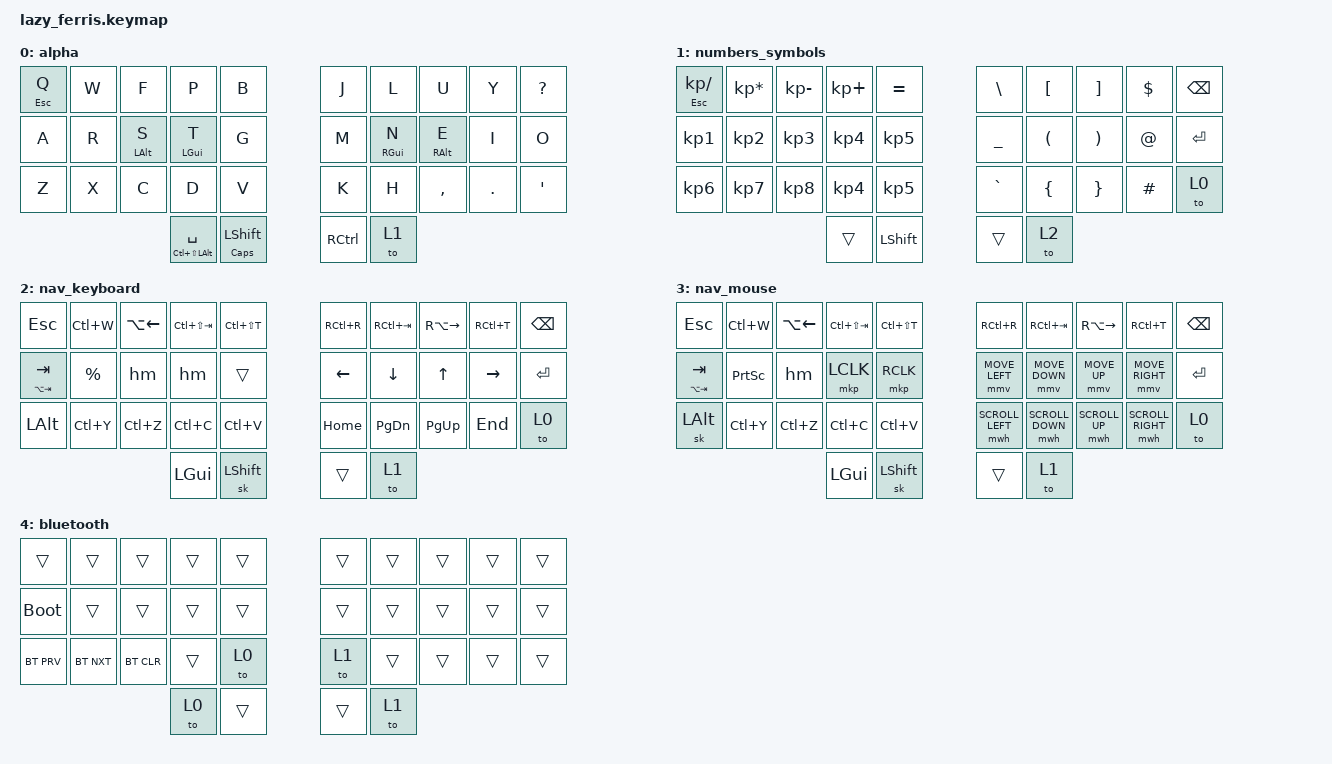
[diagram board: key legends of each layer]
/*
 * Copyright (c) 2020 The ZMK Contributors
 *
 * SPDX-License-Identifier: MIT
 */

#include <behaviors.dtsi>
#include <dt-bindings/zmk/keys.h>
#include <dt-bindings/zmk/bt.h>
#include <dt-bindings/zmk/mouse.h>

&mt {
    tapping_term_ms = <200>;
    flavor = "tap-preferred";
};

// Layers
#define ALPHA   0
#define SYMBOLS 1
#define KBNAV   2
#define MSNAV   3	
#define BLTH    4

/* 34 Key Matrix
╭──────────────╮ ╭──────────────╮
│ 0  1  2  3  4│ │ 5  6  7  8  9│
│10 11 12 13 14│ │15 16 17 18 19│
│20 21 22 23 24│ │25 26 27 28 29│
╰────────╮30 31│ │32 33╭────────╯
         ╰─────╯ ╰─────╯         
*/

/ {
    combos {
        compatible = "zmk,combos";

// General combos
        combo_to_alpha {
            timeout-ms = <50>;
            key-positions = <30 33>;
            bindings = <&to ALPHA>;
        };

        combo_caps_word {
            timeout-ms = <50>;
            key-positions = <24 25>;
            bindings = <&caps_word>;
        };

        combo_backspace {
            timeout-ms = <50>;
            key-positions = <8 9>;
            bindings = <&kp BACKSPACE>;
        };

        combo_return {
            timeout-ms = <50>;
            key-positions = <18 19>;
            bindings = <&kp RETURN>;
        };

// Alpha layer combos
/*
╭──────────────╮ ╭──────────────╮
│ 0  1  2  3  4│ │ 5  6  7  8  9│
│10 11 12 13 14│ │15 16 17 18 19│
│20 21 22 23 24│ │25 26 27 28 29│
╰────────╮30 31│ │32 33╭────────╯
         ╰─────╯ ╰─────╯         
*/
        combo_exclamation_point {
            timeout-ms = <50>;
            key-positions = <31 9>;
            bindings = <&kp EXCLAMATION>;
            layers = <ALPHA>;
        };

        combo_underscore {
            timeout-ms = <50>;
            key-positions = <21 22>;
            bindings = <&kp UNDERSCORE>;
            layers = <ALPHA>;
        };

        combo_3 {
            timeout-ms = <50>;
            key-positions = <7 8>;
            bindings = <&to 3>;
        };

        combo_ent {
            timeout-ms = <50>;
            key-positions = <27 28>;
            bindings = <&kp RET>;
        };

        combo_g {
            timeout-ms = <15>;
            key-positions = <12 13>;
            bindings = <&kp G>;
            layers = <0>;
        };

        combo_j {
            timeout-ms = <50>;
            key-positions = <22 23>;
            bindings = <&kp J>;
            layers = <0>;
        };

        combo_p {
            timeout-ms = <15>;
            key-positions = <16 17>;
            bindings = <&kp P>;
            layers = <0>;
        };

        combo_b {
            timeout-ms = <50>;
            key-positions = <26 27>;
            bindings = <&kp B>;
            layers = <0>;
        };

        combo_scol {
            timeout-ms = <50>;
            key-positions = <8 9>;
            bindings = <&kp SEMI>;
            layers = <0>;
        };

        combo_com {
            timeout-ms = <50>;
            key-positions = <20 21>;
            bindings = <&kp COMMA>;
            layers = <0>;
        };

        combo_minus {
            timeout-ms = <50>;
            key-positions = <0 1>;
            bindings = <&kp MINUS>;
            layers = <0>;
        };

        combo_slsh {
            timeout-ms = <50>;
            key-positions = <28 29>;
            bindings = <&kp SLASH>;
            layers = <0>;
        };

        combo_sqt {
            timeout-ms = <50>;
            key-positions = <12 13>;
            bindings = <&kp SQT>;
            layers = <1>;
        };

        combo_dqt {
            timeout-ms = <50>;
            key-positions = <22 23>;
            bindings = <&kp DQT>;
            layers = <1>;
        };

        combo_bslh {
            timeout-ms = <50>;
            key-positions = <16 17>;
            bindings = <&kp BSLH>;
            layers = <1>;
        };

        combo_lbkt {
            timeout-ms = <50>;
            key-positions = <26 27>;
            bindings = <&kp LBKT>;
            layers = <1>;
        };

        combo_n0 {
            timeout-ms = <50>;
            key-positions = <26 27>;
            bindings = <&kp N0>;
            layers = <2>;
        };

        combo_lalt {
            timeout-ms = <50>;
            key-positions = <12 13>;
            bindings = <&kp LALT>;
            layers = <3>;
        };

        combo_del {
            timeout-ms = <50>;
            key-positions = <22 23>;
            bindings = <&kp DEL>;
            layers = <3>;
        };

        combo_left {
            timeout-ms = <50>;
            key-positions = <16 17>;
            bindings = <&kp LEFT>;
            layers = <3>;
        };

        combo_lclk {
            timeout-ms = <50>;
            key-positions = <26 27>;
            bindings = <&mkp LCLK>;
            layers = <3>;
        };
    };

    behaviors {
        hm: homerow_mods {
            compatible = "zmk,behavior-hold-tap";
            label = "HOMEROW_MODS";
            #binding-cells = <2>;
            tapping-term-ms = <200>;
            quick_tap_ms = <0>;
            flavor = "tap-preferred";
            bindings =
                <&kp>,
                <&kp>;
        };
        hs: homerow_shifts {
            compatible = "zmk,behavior-hold-tap";
            label = "HOMEROW_SHIFTS";
            #binding-cells = <2>;
            tapping-term-ms = <150>;
            quick_tap_ms = <0>;
            flavor = "balanced";
            bindings =
                <&kp>,
                <&kp>;
        };
        hsl: homerow_shifts_layer {
            compatible = "zmk,behavior-hold-tap";
            label = "HOMEROW_SHIFTS_LAYER";
            #binding-cells = <2>;
            tapping-term-ms = <150>;
            quick_tap_ms = <0>;
            flavor = "balanced";
            bindings =
                <&kp>,
                <&to>;
        };
        td: tapdance {
            compatible = "zmk,behavior-hold-tap";
            label = "TAPDANCE";
            #binding-cells = <2>;
            tapping-term-ms = <150>;
            quick_tap_ms = <0>;
            flavor = "tap-preferred";
            bindings =
                <&kp>,
                <&kp>;
        };
        bl: layertap {
            compatible = "zmk,behavior-hold-tap";
            label = "LAYERTAP";
            #binding-cells = <2>;
            tapping-term-ms = <150>;
            quick_tap_ms = <0>;
            flavor = "tap-preferred";
            bindings =
                <&to>,
                <&kp>;
        };
    };

    /* 34 Keys
╭──────────────╮ ╭──────────────╮
│ 0  1  2  3  4│ │ 5  6  7  8  9│
│10 11 12 13 14│ │15 16 17 18 19│
│20 21 22 23 24│ │25 26 27 28 29│
╰────────╮30 31│ │32 33╭────────╯
         ╰─────╯ ╰─────╯         
    */

    keymap {
        compatible = "zmk,keymap";

        alpha {
/* Alphas
---------------------------------------------------------------------------------------------------------------------
|    Q    |    W    |    F    |    P    |    B    |          |    J    |    L    |    U    |    Y    | ? (+:!) (^:_)|
|    A    |    R    |    S    |    T    |    G    |          |    M    |    N    |    E    |    I    |    O    |
|    Z    |    X    |    C    |    D    |    V    |          |    K    |    H    |, (+: ;) |. (+: :) |' (+: ") |
          |   SPACE (h:MEH)   |   SHIFT (h:CAPS)  |          |       CTRL        | L2 (+:L3) (h:L4)  |
---------------------------------------------------------------------------------------------------------------------
*/
            bindings = <
&ht ESC Q   &kp W   &kp F       &kp P       &kp B               &kp J   &kp L       &kp U       &kp Y       &kp QMARK
&kp A       &kp R   &hm LALT S  &hm LGUI T  &kp G               &kp M   &hm RGUI N  &hm RALT E  &kp I       &kp O
&kp Z       &kp X   &kp C       &kp D       &kp V               &kp K   &kp H       &kp COMMA   &kp PERIOD  &kp APOSTROPHE
                    &mt LC(LS(LALT)) SPACE  &ht CAPS LSHIFT     &kp RCTRL   &to 1
            >;
        };

        numbers_symbols {
/* Numbers and Symbols 
---------------------------------------------------------------------------------------------------------------------
| / (+:%) | * (+:^) |    -    | + (+:&) |    =    |          | \ (+:|) |    [    |    ]    | $ (+:₪) |  BSPACE |
|    1    |    2    |    3    |    4    |    5    |          |    _    | ( (+:<) | ) (+:>) |    @    |  ENTER  |
|    6    |    7    |    8    |    9    |    0    |          | ` (+:~) |    {    |    }    |    #    |  TO L0  |
          |   SPACE (h:MEH)   |   SHIFT (h:FN)    |          |       CTRL        |   L2     (+:L3)   |
---------------------------------------------------------------------------------------------------------------------
*/
            bindings = <
&ht ESC KP_SLASH    &kp KP_MULTIPLY &kp KP_MINUS    &kp KP_PLUS &kp EQUAL   &kp BACKSLASH   &kp LBKT    &kp RBKT    &kp DLLR    &kp BSPC
&kp KP_N1           &kp KP_N2       &kp KP_N3       &kp KP_N4   &kp KP_N5   &kp UNDER       &kp LPAR    &kp RPAR    &kp AT_SIGN &kp RET
&kp KP_N6           &kp KP_N7       &kp KP_N8       &kp KP_N4   &kp KP_N5   &kp GRAVE       &kp LBRC    &kp RBRC    &kp HASH    &to 0
                                    &trans          &kp LSHIFT  &trans      &to 2
            >;
        };

        nav_keyboard {
/* Keyboard Navigation
----------------------------------------------------------------------------------------------------------------------------
|   ESC        | EXIT TAB | PREV PAGE | PREV TAB | REOP TAB |         | REFRESH | NEXT TAB | NEXT PAGE | NEW TAB |  BSPACE |
| TAB (h:alt+) |          |           |          |          |         | LARROW  | DARROW   | UARROW    | RARROW  |  ENTER  |
|    ALT       |   REDO   |    UNDO   |   COPY   |   PASTE  |         |  HOME   |  PG DN   |  PG UP    |   END   |  TO L0  |
          |   SPACE (h:MEH)   |   SHIFT (h:FN)    |          |       CTRL        |   L2     (+:L3)   |
----------------------------------------------------------------------------------------------------------------------------
*/
            bindings = <
&kp ESC         &kp LC(W) &kp LA(LEFT)    &kp LC(LS(TAB)) &kp LC(LS(T)) &kp RC(R) &kp RC(TAB) &kp RA(RIGHT)   &kp RC(T)   &kp BSPC
&mt LA(TAB) TAB &kp PRCNT &hm             &hm             &trans        &kp LEFT  &kp DOWN    &kp UP          &kp RIGHT   &kp RET
&kp LALT        &kp LC(Y) &kp LC(Z)       &kp LC(C)       &kp LC(V)     &kp HOME  &kp PG_DN   &kp PG_UP       &kp END     &to 0
                                          &kp LGUI        &sk LSHIFT    &trans &to 1
            >;
        };

        nav_mouse {
/* Mouse Navigation
----------------------------------------------------------------------------------------------------------------------------
|   ESC        | EXIT TAB | PREV PAGE | PREV TAB | REOP TAB |         | REFRESH | NEXT TAB | NEXT PAGE | NEW TAB |  BSPACE |
| TAB (h:alt+) |          |           |          |          |         | LMOUSE  | DMOUSE   | UMOUSE    | RMOUSE  |  ENTER  |
|    ALT       |   REDO   |    UNDO   |   COPY   |   PASTE  |         |  HOME   |  PG DN   |  PG UP    |   END   |  TO L0  |
          |   SPACE (h:MEH)   |   SHIFT (h:FN)    |          |       CTRL        |   L2     (+:L3)   |
----------------------------------------------------------------------------------------------------------------------------
*/
            bindings = <
&kp ESC         &kp LC(W) &kp LA(LEFT) &kp LC(LS(TAB)) &kp LC(LS(T)) &kp RC(R)        &kp RC(TAB)      &kp RA(RIGHT)  &kp RC(T)         &kp BSPC
&mt LA(TAB) TAB &kp PSCRN &hm          &mkp LCLK       &mkp RCLK     &mmv MOVE_LEFT   &mmv MOVE_DOWN   &mmv MOVE_UP   &mmv MOVE_RIGHT   &kp RET
&sk LALT        &kp LC(Y) &kp LC(Z)    &kp LC(C)       &kp LC(V)     &mwh SCROLL_LEFT &mwh SCROLL_DOWN &mwh SCROLL_UP &mwh SCROLL_RIGHT &to 0
                                       &kp LGUI        &sk LSHIFT    &trans        &to 1
            >;
        };

        bluetooth {
// Bluetooth
            bindings = <
      &trans      &trans      &trans  &trans  &trans  &trans  &trans  &trans  &trans  &trans
 &bootloader      &trans      &trans  &trans  &trans  &trans  &trans  &trans  &trans  &trans
  &bt BT_PRV  &bt BT_NXT  &bt BT_CLR  &trans   &to 0   &to 1  &trans  &trans  &trans  &trans
                                       &to 0  &trans  &trans   &to 1
            >;
        };
    };
};
